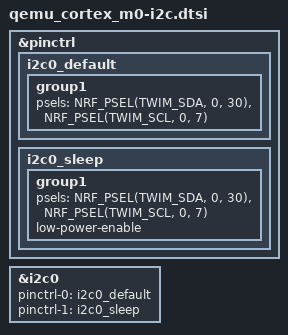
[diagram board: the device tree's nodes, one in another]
/*
 * Copyright (c) 2024 Chaim Zax
 * SPDX-License-Identifier: Apache-2.0
 */

#include "adxl34x-i2c.dtsi"

&pinctrl {
	i2c0_default: i2c0_default {
		group1 {
			psels = <NRF_PSEL(TWIM_SDA, 0, 30)>,
				<NRF_PSEL(TWIM_SCL, 0, 7)>;
		};
	};

	i2c0_sleep: i2c0_sleep {
		group1 {
			psels = <NRF_PSEL(TWIM_SDA, 0, 30)>,
				<NRF_PSEL(TWIM_SCL, 0, 7)>;
			low-power-enable;
		};
	};
};

&i2c0 {
	status = "okay";
	pinctrl-0 = <&i2c0_default>;
	pinctrl-1 = <&i2c0_sleep>;
	pinctrl-names = "default", "sleep";
};
